# RS14100 register map
File version: 1.0
CPU: CM4 r0p1, little endian, MPU, FPU, 4 interrupt priority bits
Registers are 32-bit, read-write, reset 0x0 unless marked. A register's access mark holds for its fields unless they carry their own. Offsets are from the block's base; [hi:lo] are bit positions; 'fields as' and 'values as' point back to an identical list.

## I2S0 — I2S(Inter-IC Sound) is transferring two-channel digital audio data from one IC device to another
Base 0x47050000
Same registers: I2S1 0x24040400
0x00 IER — I2S Enable Register
  [0] IEN — Inter Block Enable
    0=Disable DWP_apb_i2s; 1=Enable DWP_apb_i2s
0x04 IRER — I2S Receiver Block Enable Register
  [0] RXEN — Receive Block Enable, Bit Overrides any Individual Receive Channel Enables
    0=Disable Receiver; 1=Enable Receiver
0x08 ITER — Transmitter Block Enable
  [0] TXEN — Transmitter Block Enable, Bit Overrides any Individual Transmit Channel Enables
    0=Disable (Transmit channel is disabled); 1=Enable (Transmit channel is enabled)
0x0C CER — Clock Enable Register
  [0] CLKEN — Clock generation enable/disable
    0=Disable (none); 1=Enable (none)
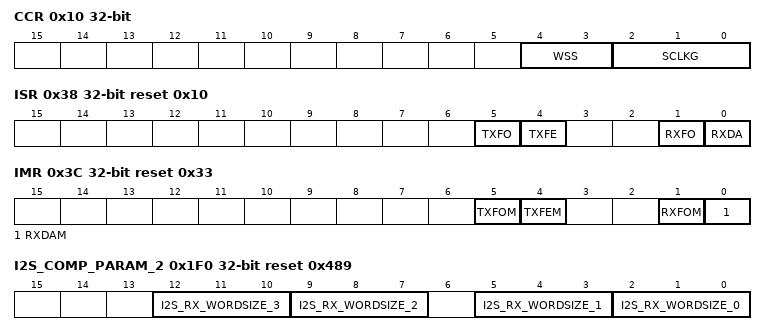
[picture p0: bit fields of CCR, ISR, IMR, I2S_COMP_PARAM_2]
0x10 CCR (reset mask 0x1) — Clock Configuration Register
  [4:3] WSS — These bits are used to program the number of sclk cycles
  [2:0] SCLKG — These bits are used to program the gating of sclk
0x14 RXFFR wo — Receiver Block FIFO Reset Register
  [0] RXFFR — Writing a 1 To This Register Flushes All The RX FIFO's Receiver Block Must be Disable Prior to Writing This Bit
0x18 TXFFR wo — Transmitter Block FIFO Reset Register
  [0] TXFFR — Writing a 1 To This Register Flushes All The RX FIFO's Receiver Block Must be Disable Prior to Writing This Bit
0x20 LRBR ro — Left Receive Buffer Register
  [15:0] LRBR — Data received serially from the received channel input
0x20 LTHR wo (alternate view of LRBR) — Left Receive Buffer Register
  [15:0] LTHR — The Left Stereo Data to be transmitted serially from the Transmitted channel output
0x24 RRBR ro — Right Receive Buffer Register
  [15:0] RRBR — The Right Stereo Data received serially from the received channel input through this register
0x24 RTHR wo (alternate view of RRBR) — Right Transmit Holding Register
  [15:0] RTHR — The Right Stereo Data to be transmitted serially from the Transmit channel output written through this register
0x28 RER reset 0x1 — Receive Enable Register
  [0] RXCHEN — This Bit enables/disables a receive channel independently of all other channels
    0=Disable (Receive Channel is Disable); 1=Enable (Receive Channel is Disable)
0x2C TER reset 0x1 — Transmit Enable Register
  [0] TXCHEN — This Bit enables/disables a transmit channel independently of all other channels
    0=Disable (Transmit Channel is Disable); 1=Enable (Transmit Channel is Enable)
0x30 RCR reset 0x2 — Receive Configuration Register
  [2:0] WLEN — This Bits are used to program the desired data resolution of the receiver and enables LSB of the incoming left or right word
    0=Ignore Word Length; 1=12 Bit Resolution; 2=16 Bit Resolution; 3=20 Bit Resolution; 4=24 Bit Resolution; 5=32 Bit Resolution
0x34 TCR reset 0x2 — Transmit Configuration Register
  [2:0] WLEN — This Bits are used to program the desired data resolution of the transmitter and ensure that MSB of the data is transmitted first.
    values as RCR.WLEN
0x38 ISR ro reset 0x10 — Interrupt Status Register
  [5] TXFO — Transmit FIFO
    0=VALID (TX FIFO Write valid); 1=OVERRUN (TX FIFO Write overrun)
  [4] TXFE — Transmit FIFO Empty
    1=TRIGGER_REACHED (trigger level reached); 0=TRIGGER_NOT_REACHED (trigger level not reached)
  [1] RXFO — Receive Data FIFO
    0=VALID (RX FIFO Write valid); 1=OVERRUN (RX FIFO Write overrun)
  [0] RXDA — Receive Data Available
    values as TXFE
0x3C IMR reset 0x33 — Interrupt Mask Register
  [all] fields
    1=MASK_INTERRUPT; 0=UNMASK_INTERRUPT
  [5] TXFOM — TX FIFO Overrun Interrupt
  [4] TXFEM — TX FIFO Empty Interrupt
  [1] RXFOM — RX FIFO Overrun Mask Interrupt
  [0] RXDAM — RX Data Available Mask Interrupt
0x40 ROR ro — Receive Overrun Register
  [0] RXCHO — Read this bit to clear the RX FIFO data overrun interrupt
    1=OVERRUN (RX FIFO Write Overrun); 0=VALID (RX FIFO Write Valid)
0x44 TOR ro — Transmit Overrun Register
  [0] RXCHO — Read this bit to clear the TX FIFO data overrun interrupt
    1=OVERRUN (TX FIFO Write Overrun); 0=VALID (TX FIFO Write Valid)
0x48 RFCRx reset 0x3 — Receive FIFO Configuration Register0
  [3:0] RXCHDT — This bits program the trigger level in the RX FIFO at which the data available interrupt is generated
0x4C TXFCRx reset 0x3 — Transmit FIFO Configuration Register
  [3:0] TXCHET — This bits program the trigger level in the TX FIFO at which the Empty Threshold Reached interrupt is generated
0x50 RFF wo — Receive FIFO Flush
  [0] RXCHFR — Writing a 1 to this register flushes an individual RX FIFO RX channel or block must be disable prior to writing to this bit
0x54 TFF wo — Transmit FIFO Flush
  [0] TXCHFR — Writing a 1 to this register flushes an individual TX FIFO TX channel or block must be disable prior to writing to this bit
0x1C0 RXDMA ro — Receiver Block DMA Register
  [15:0] RXDMA — Used to cycle repeatedly through the enabled receive channels Reading stereo data pairs
0x1C4 RRXDMA wo — Reset Receiver Block DMA Register
  [0] RRXDMA — Writing a 1 to this self-clearing register resets the RXDMA register
0x1C8 TXDMA wo — Transmitter Block DMA Register
  [15:0] RXDMA — Used to cycle repeatedly through the enabled transmit channels allow to writing of stereo data pairs
0x1CC RTXDMA wo — Reset Transmitter Block DMA Register
  [0] RTXDMA — Writing a 1 to this self-clearing register resets the TXDMA register
0x1F0 I2S_COMP_PARAM_2 ro reset 0x489 — Component Parameter 2 Register
  [12:10] I2S_RX_WORDSIZE_3 — On Read returns the value of word size of receiver channel 3
    0=12 Bit resolution; 1=16 Bit resolution; 2=20 Bit resolution; 3=24 Bit resolution; 4=32 Bit resolution
  [9:7] I2S_RX_WORDSIZE_2 — On Read returns the value of word size of receiver channel 2
  [5:3] I2S_RX_WORDSIZE_1 — On Read returns the value of word size of receiver channel 1
  [2:0] I2S_RX_WORDSIZE_0 — On Read returns the value of word size of receiver channel 0
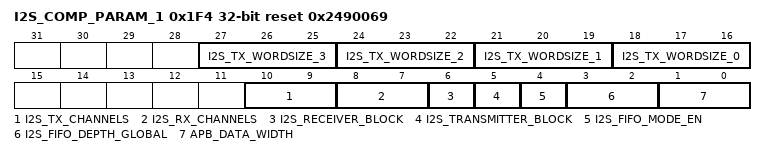
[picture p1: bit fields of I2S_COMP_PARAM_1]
0x1F4 I2S_COMP_PARAM_1 ro reset 0x2490069 — Component Parameter 1 Register
  [27:25] I2S_TX_WORDSIZE_3 — On Read returns the value of word size of transmitter channel 3
    values as I2S_COMP_PARAM_2.I2S_RX_WORDSIZE_3
  [24:22] I2S_TX_WORDSIZE_2 — Returns the value of word size of transmitter channel 2
  [21:19] I2S_TX_WORDSIZE_1 — Returns the value of word size of transmitter channel 1
  [18:16] I2S_TX_WORDSIZE_0 — Returns the value of word size of transmitter channel 0
  [10:9] I2S_TX_CHANNELS — Returns the number of transmitter channels
    0=1 Channel; 1=2 Channels; 2=3 Channels; 3=4 Channels
  [8:7] I2S_RX_CHANNELS — Returns the number of receiver channels
    0=1 Channel; 1=2 Channels; 2=3 Channels; 3=4 Channels
  [6] I2S_RECEIVER_BLOCK — Shows the presence of the receiver block
    0=BLOCK_ABSENT (Block not present); 1=BLOCK_PRESENT (Block is present)
  [5] I2S_TRANSMITTER_BLOCK — Shows the presence of the transmitter block
    values as I2S_RECEIVER_BLOCK
  [4] I2S_FIFO_MODE_EN — Determines whether component act as Master or Slave
    0=Slave (Mode); 1=Master (Mode)
  [3:2] I2S_FIFO_DEPTH_GLOBAL — Determines FIFO depth for all channels
    0=2 Words deep; 1=4 Words deep; 2=8 Words deep; 3=16 words deep
  [1:0] APB_DATA_WIDTH — Width of APB data bus
    0=8 Bits; 1=16 Bits; 2=32 Bits; 3=none
0x1F8 I2S_COMP_VERSION_REG ro reset 0x3130362A — Component Version ID
  [31:0] I2S_COMP_VERSION — Return the component version(1.02)
0x1FC I2S_COMP_TYPE_REG ro reset 0x445701A0 — Component Type
  [31:0] I2S_COMP_TYPE — Return the component type
